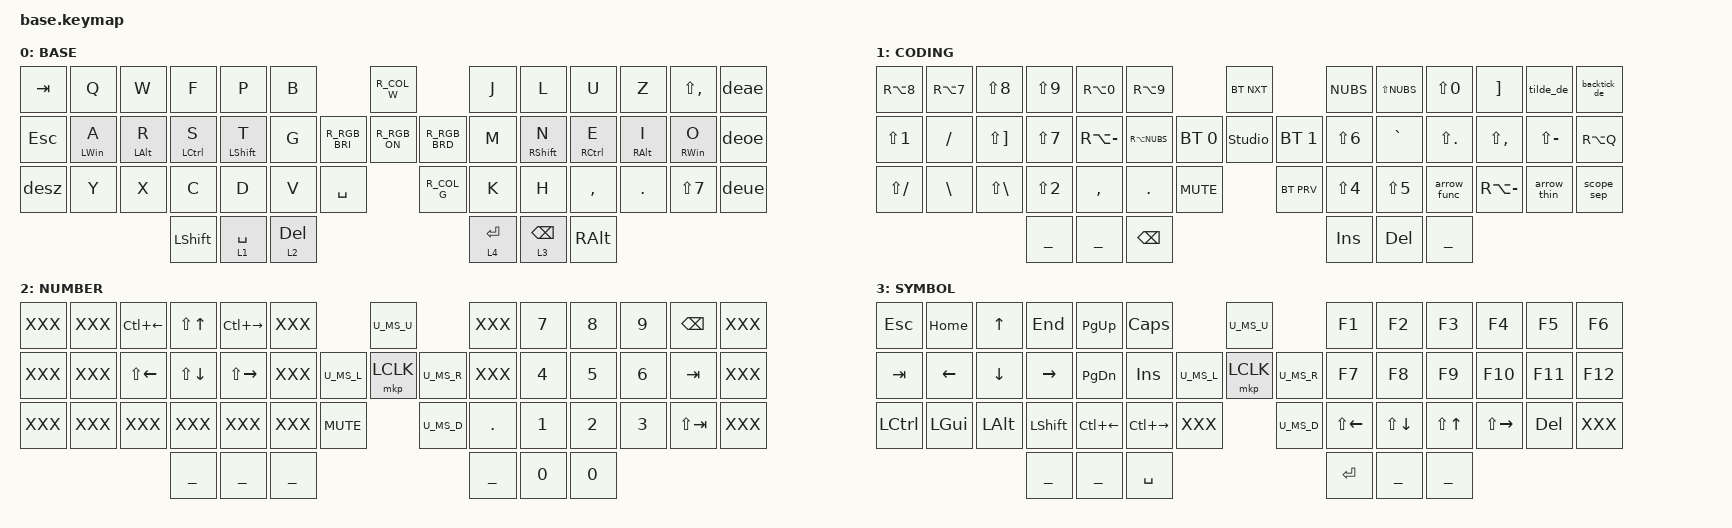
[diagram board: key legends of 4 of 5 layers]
// Define layer numbers
#define BASE 0
#define BASE_QWERTY 1
#define NAV_WORD 2
#define NUM_WORD 3
#define SYM_WORD 4
#define NAV 5
#define NUM 6
#define SYM 7
#define FUNC 8
#define ADJUST 9
#define LOWER 10
#define MOUSE_KEYS 11
#define MOUSE_TP 12
#define MOUSE_TP_KEYS 13
#define MOUSE_TP_SET 14

#ifdef HAS_UROB
  #define HAS_TRI_STATE
  #define HAS_NUM_WORD
#endif



// ZMK includes
#include <behaviors.dtsi>
#include <dt-bindings/zmk/bt.h>
#include <dt-bindings/zmk/keys.h>
#include <dt-bindings/zmk/outputs.h>

// Personal includes
#include "includes/zmk_on_ger_leyout.dsti"
#include "includes/rgb.dtsi"
#include "includes/custom_keycodes.dtsi"
#include "includes/settings.dtsi"
//#include "includes/settings_pd.dtsi"
#include "includes/conditional_layers.dtsi"
#include "includes/macros.dtsi"
#include "includes/combos.dtsi"
#include "includes/behaviours_homerow_mods.dtsi"
#include "includes/behaviours_mod_morph.dtsi"
#include "includes/behaviours_other.dtsi"



/ {
    /* behaviors {
        td0: td0 {
            compatible = "zmk,behavior-tap-dance";
            display-name = "Shift/Caps Lock Tap Dance";
            #binding-cells = <0>;
            bindings = <&kp LEFT_SHIFT>, <&kp CAPS>;
        };
    }; */

   #include "includes/sensor_encder.dtsi"

    

    keymap {
        compatible = "zmk,keymap";

        default_layer {
            display-name = "BASE";
            bindings = <
&kp TAB  &kp Q            &kp W            &kp F         &kp P         &kp B                                    R_COL_W                     &kp J        &kp L            &kp U         &kp Z             &kp LS(COMMA)     &deae
&kp ESC  &hm_l LEFT_WIN A  &hm_l LEFT_ALT R  &hm_l LCTRL S  &hm_l LSHIFT T &kp G                  R_RGB_BRI  R_RGB_ON  R_RGB_BRD  &kp M        &hm_r RSHIFT N    &hm_r RCTRL E  &hm_r RIGHT_ALT I  &hm_r RIGHT_WIN O  &deoe
&desz    &kp Y            &kp X            &kp C         &kp D         &kp V      &kp SPACE                     R_COL_G                   &kp K        &kp H            &kp COMMA     &kp DOT           &kp LS(N7)        &deue
                                           &kp LSHIFT    &lt 1 SPACE   &lt 2 DEL                                                                                   &lt 4 ENTER  &lt 3 BACKSPACE  &kp RALT
            >;

            sensor-bindings = <&inc_dec_kp C_VOLUME_UP C_VOLUME_DOWN>;
        };

        /* ================= CODING (RAISE inhaltlich) ================= */
        // -------------------------------------------------------------------------------------------------------
        // |  [  |  {  |  (  |  )  |  }  |  ]  |     |     |     |  G  |     |  <  |  >  |  =  |  +  |  ~  |  `  |
        // |  !  |  -  |  *  |  /  |  \  |  |  |     |     |  G  |  G  |  G  |  &  |  ^  |  :  |  ;  |  ?  |  @  |
        // |  _  |  #  |  '  |  "  |  ,  |  .  | SPC |     |     |  G  |     |  $  |  %  |  => |  \  |  -> |  :: |
        //                   |     |     |     |     |     |     |     |     |     |     |     |

        lower_layer {
            display-name = "CODING";

            /* DE-Host-sichere Klammern/Operatoren + deine festen RGB/SPACE/MMV-Slots */

            bindings = <
&kp RA(N8)     &kp RA(N7)  &kp LS(N8)    &kp LS(N9)  &kp RA(N0)     &kp RA(N9)                                            &bt BT_NXT                    &kp NUBS    &kp LS(NUBS)  &kp LS(N0)   &kp RBKT       &tilde_de        &backtick_de
&kp LS(N1)     &kp FSLH    &kp LS(RBKT)  &kp LS(N7)  &kp RA(MINUS)  &kp RA(NUBS)                            &bt BT_SEL 0  &studio_unlock  &bt BT_SEL 1  &kp LS(N6)  &kp GRAVE     &kp LS(DOT)  &kp LS(COMMA)  &kp LS(MINUS)    &kp RA(Q)
&kp LS(FSLH)   &kp BSLH    &kp LS(BSLH)  &kp LS(N2)  &kp COMMA      &kp DOT                   &kp C_MUTE                  &bt BT_PRV                    &kp LS(N4)  &kp LS(N5)    &arrow_func  &kp RA(MINUS)  &arrow_thin      &scope_sep
                                         ___      ___         &kp BSPC                                                                            &kp INS     &kp DEL       ___
            >;

            sensor-bindings = <&scroll_encoder>;
        };

        /* ================= NUMBER (Num/Operatoren + Macros) ================= */
        // -------------------------------------------------------------------------------------------------------
        // |     |     |     |     |     |     |     |     |     |  G  |     |     |  7  |  8  |  9  | BSPC |     |
        // |     |     |     |     |     |     |     |     |  G  |  G  |  G  |     |  4  |  5  |  6  | TAB  |     |
        // |     |     |     |     |     |     | SPC |     |     |  G  |     |  .  |  1  |  2  |  3  | RTAB |     |
        //                   |     |     |     |     |     |     |     |     |     |  0  |  0  |

        num_layer {
            display-name = "NUMBER";
            bindings = <
XXX  XXX  &kp LC(LEFT)  &kp LS(UP)    &kp LC(RIGHT)  XXX                                U_MS_U                     XXX   &kp N7  &kp N8  &kp N9  &kp BACKSPACE  XXX
XXX  XXX  &kp LS(LEFT)  &kp LS(DOWN)  &kp LS(RIGHT)  XXX                U_MS_L  &mkp LCLK       U_MS_R  XXX   &kp N4  &kp N5  &kp N6  &kp TAB        XXX
XXX  XXX  XXX        XXX        XXX         XXX  &kp C_MUTE                    U_MS_D                   &kp DOT  &kp N1  &kp N2  &kp N3  &kp LS(TAB)    XXX
                              ___        ___         ___                                                                 ___   &kp N0  &kp N0
            >;

            sensor-bindings = <&scroll_encoder>;
        };

        /* ================= SYMBOL (Navigation/Editing) ================= */

        raise_layer {
            display-name = "SYMBOL";
            bindings = <
&kp ESC    &kp HOME  &kp UP    &kp END    &kp PG_UP     &kp CAPS                                 U_MS_U                     &kp F1        &kp F2        &kp F3      &kp F4         &kp F5   &kp F6
&kp TAB    &kp LEFT  &kp DOWN  &kp RIGHT  &kp PG_DN     &kp INS                  U_MS_L  &mkp LCLK       U_MS_R  &kp F7        &kp F8        &kp F9      &kp F10        &kp F11  &kp F12
&kp LCTRL  &kp LGUI  &kp LALT  &kp LSHFT  &kp LC(LEFT)  &kp LC(RIGHT)  XXX                    U_MS_D                   &kp LS(LEFT)  &kp LS(DOWN)  &kp LS(UP)  &kp LS(RIGHT)  &kp DEL  XXX
                               ___     ___        &kp SPACE                                                                 &kp RET       ___        ___
            >;

            sensor-bindings = <&scroll_encoder>;
        };

        /* ================= SYS (Bluetooth / Output / RGB / Backlight) ================= */

        sys_layer {
            display-name = "SYS";
            bindings = <
&bt BT_SEL 0     &bt BT_SEL 1     &bt BT_SEL 2     &bt BT_SEL 3     &bt BT_SEL 4     &bt BT_NXT                                     U_MS_U                     &bt BT_PRV       &bt BT_CLR       &bt BT_CLR_ALL   &out OUT_USB     &out OUT_BLE  &out OUT_TOG
&rgb_ug RGB_TOG  &rgb_ug RGB_HUI  &rgb_ug RGB_HUD  &rgb_ug RGB_SAI  &rgb_ug RGB_SAD  &rgb_ug RGB_EFF                U_MS_L  &mkp LCLK       U_MS_R  &rgb_ug RGB_BRI  &rgb_ug RGB_BRD  &rgb_ug RGB_SPI  &rgb_ug RGB_SPD  XXX        XXX
&bl BL_TOG       &bl BL_INC       &bl BL_DEC       &bl BL_CYCLE     &bl BL_SET 50    &bl BL_OFF       &kp C_MUTE                    U_MS_D                   &bootloader      &studio_unlock   XXX           XXX           XXX        XXX
                                                   ___           ___           ___                                                                          ___           ___           ___
            >;

            sensor-bindings = <&scroll_encoder>;
        };
    };
};
